# MSP430F5529 register map
Vendor: msp430gen; File version: VERGEN_IDEMPOTENT_OUTPUT
Registers are 8-bit, read-write, reset 0x0 unless marked. A register's access mark holds for its fields unless they carry their own. Offsets are from the block's base; [hi:lo] are bit positions; {n}, {i} and the like mark numbered series.

## RTC — RTC Real Time Clock
Base 0x000004A0
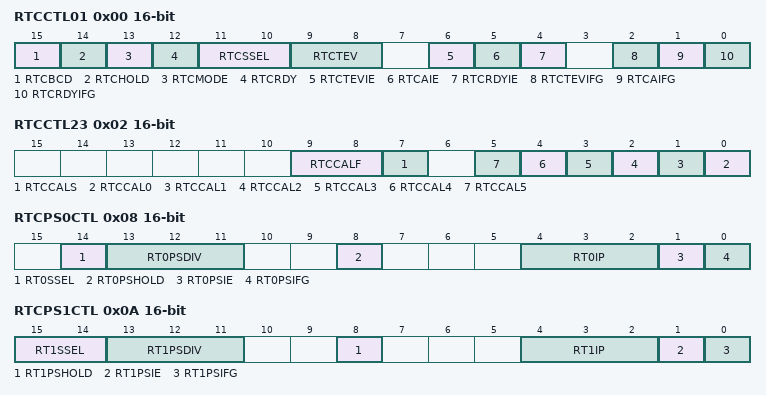
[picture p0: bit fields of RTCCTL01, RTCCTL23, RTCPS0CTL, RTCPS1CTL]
0x00 RTCCTL01 16-bit — Real Timer Control 0/1
  [15] RTCBCD — RTC BCD 0:Binary / 1:BCD
  [14] RTCHOLD
  [13] RTCMODE — RTC Mode 0:Counter / 1: Calendar
  [12] RTCRDY — RTC Ready
  [11:10] RTCSSEL — RTC Source Select 1
    0=RTC Source Select ACLK; 1=RTC Source Select SMCLK; 2=RTC Source Select RT1PS; 3=RTC Source Select RT1PS
  [9:8] RTCTEV — RTC Time Event 1
    0=RTC Time Event: 0 (Min. changed); 1=RTC Time Event: 1 (Hour changed); 2=RTC Time Event: 2 (12:00 changed); 3=RTC Time Event: 3 (00:00 changed)
  [6] RTCTEVIE — RTC Time Event Interrupt Enable Flag
  [5] RTCAIE — RTC Alarm Interrupt Enable Flag
  [4] RTCRDYIE — RTC Ready Interrupt Enable Flag
  [2] RTCTEVIFG — RTC Time Event Interrupt Flag
  [1] RTCAIFG — RTC Alarm Interrupt Flag
  [0] RTCRDYIFG — RTC Ready Interrupt Flag
0x02 RTCCTL23 16-bit — Real Timer Control 2/3
  [9:8] RTCCALF — RTC Calibration Frequency Bit 1
    0=RTC Calibration Frequency: No Output; 1=RTC Calibration Frequency: 512 Hz; 2=RTC Calibration Frequency: 256 Hz; 3=RTC Calibration Frequency: 1 Hz
  [7] RTCCALS — RTC Calibration Sign
  [n] RTCCAL{n} (n=0..5) — RTC Calibration Bit {n}
0x08 RTCPS0CTL 16-bit — Real Timer Prescale Timer 0 Control
  [14] RT0SSEL — RTC Prescale Timer 0 Source Select 0:ACLK / 1:SMCLK
  [13:11] RT0PSDIV — RTC Prescale Timer 0 Clock Divide Bit: 2
    0=RTC Prescale Timer 0 Clock Divide /2; 1=RTC Prescale Timer 0 Clock Divide /4; 2=RTC Prescale Timer 0 Clock Divide /8; 3=RTC Prescale Timer 0 Clock Divide /16; 4=RTC Prescale Timer 0 Clock Divide /32; 5=RTC Prescale Timer 0 Clock Divide /64; 6=RTC Prescale Timer 0 Clock Divide /128; 7=RTC Prescale Timer 0 Clock Divide /256
  [8] RT0PSHOLD — RTC Prescale Timer 0 Hold
  [4:2] RT0IP — RTC Prescale Timer 0 Interrupt Interval Bit: 2
    0=RTC Prescale Timer 0 Interrupt Interval /2; 1=RTC Prescale Timer 0 Interrupt Interval /4; 2=RTC Prescale Timer 0 Interrupt Interval /8; 3=RTC Prescale Timer 0 Interrupt Interval /16; 4=RTC Prescale Timer 0 Interrupt Interval /32; 5=RTC Prescale Timer 0 Interrupt Interval /64; 6=RTC Prescale Timer 0 Interrupt Interval /128; 7=RTC Prescale Timer 0 Interrupt Interval /256
  [1] RT0PSIE — RTC Prescale Timer 0 Interrupt Enable Flag
  [0] RT0PSIFG — RTC Prescale Timer 0 Interrupt Flag
0x0A RTCPS1CTL 16-bit — Real Timer Prescale Timer 1 Control
  [15:14] RT1SSEL — RTC Prescale Timer 1 Source Select Bit 1
    0=RTC Prescale Timer Source Select ACLK; 1=RTC Prescale Timer Source Select SMCLK; 2=RTC Prescale Timer Source Select RT0PS; 3=RTC Prescale Timer Source Select RT0PS
  [13:11] RT1PSDIV — RTC Prescale Timer 1 Clock Divide Bit: 2
    0=RTC Prescale Timer 1 Clock Divide /2; 1=RTC Prescale Timer 1 Clock Divide /4; 2=RTC Prescale Timer 1 Clock Divide /8; 3=RTC Prescale Timer 1 Clock Divide /16; 4=RTC Prescale Timer 1 Clock Divide /32; 5=RTC Prescale Timer 1 Clock Divide /64; 6=RTC Prescale Timer 1 Clock Divide /128; 7=RTC Prescale Timer 1 Clock Divide /256
  [8] RT1PSHOLD — RTC Prescale Timer 1 Hold
  [4:2] RT1IP — RTC Prescale Timer 1 Interrupt Interval Bit: 2
    0=RTC Prescale Timer 1 Interrupt Interval /2; 1=RTC Prescale Timer 1 Interrupt Interval /4; 2=RTC Prescale Timer 1 Interrupt Interval /8; 3=RTC Prescale Timer 1 Interrupt Interval /16; 4=RTC Prescale Timer 1 Interrupt Interval /32; 5=RTC Prescale Timer 1 Interrupt Interval /64; 6=RTC Prescale Timer 1 Interrupt Interval /128; 7=RTC Prescale Timer 1 Interrupt Interval /256
  [1] RT1PSIE — RTC Prescale Timer 1 Interrupt Enable Flag
  [0] RT1PSIFG — RTC Prescale Timer 1 Interrupt Flag
0x0C RTCPS 16-bit — Real Timer Prescale Timer Control
0x0E RTCIV 16-bit — Real Time Clock Interrupt Vector
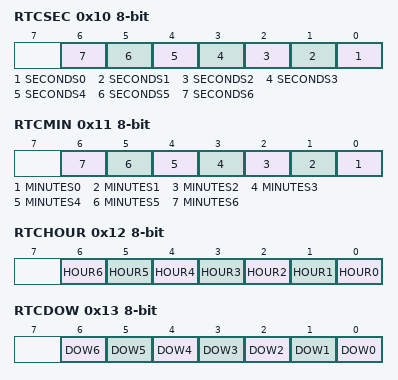
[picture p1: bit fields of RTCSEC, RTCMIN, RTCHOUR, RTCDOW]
0x10 RTCSEC — Real Time Clock Seconds
  [n] SECONDS{n} (n=0..6) — Real Time Clock Seconds Bit: {n}
0x11 RTCMIN — Real Time Clock Minutes
  [n] MINUTES{n} (n=0..6) — Real Time Clock Minutes Bit: {n}
0x12 RTCHOUR — Real Time Clock Hour
  [n] HOUR{n} (n=0..6) — Real Time Clock Hour Bit: {n}
0x13 RTCDOW — Real Time Clock Day of week
  [n] DOW{n} (n=0..6) — Real Time Clock DOW Bit: {n}
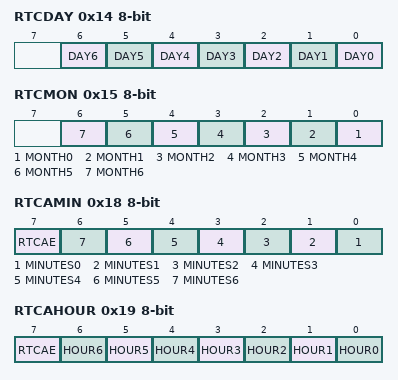
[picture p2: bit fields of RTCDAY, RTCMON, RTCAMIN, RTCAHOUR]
0x14 RTCDAY — Real Time Clock Day
  [n] DAY{n} (n=0..6) — Real Time Clock Day Bit: {n}
0x15 RTCMON — Real Time Clock Month
  [n] MONTH{n} (n=0..6) — Real Time Clock Month Bit: {n}
0x16 RTCYEAR 16-bit — Real Time Clock Year
0x18 RTCAMIN — Real Time Clock Alarm Min
  [7] RTCAE — Real Time Clock Alarm enable
  [n] MINUTES{n} (n=0..6) — Real Time Clock Minutes Bit: {n}
0x19 RTCAHOUR — Real Time Clock Alarm Hour
  [7] RTCAE — Real Time Clock Alarm enable
  [n] HOUR{n} (n=0..6) — Real Time Clock Hour Bit: {n}
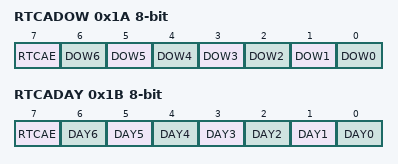
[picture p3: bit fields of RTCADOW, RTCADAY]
0x1A RTCADOW — Real Time Clock Alarm Day of week
  [7] RTCAE — Real Time Clock Alarm enable
  [n] DOW{n} (n=0..6) — Real Time Clock DOW Bit: {n}
0x1B RTCADAY — Real Time Clock Alarm Day
  [7] RTCAE — Real Time Clock Alarm enable
  [n] DAY{n} (n=0..6) — Real Time Clock Day Bit: {n}
